VERSION ""

NS_ :

BS_:

BU_: XXX

BO_ 85 CID_FEHZVD: 8 XXX
 SG_ sig_qmhbra : 40|1@1+ (1,0) [0|1] "" XXX
 SG_ sig_kxugde : 56|8@1+ (1,0) [0|255] "" XXX

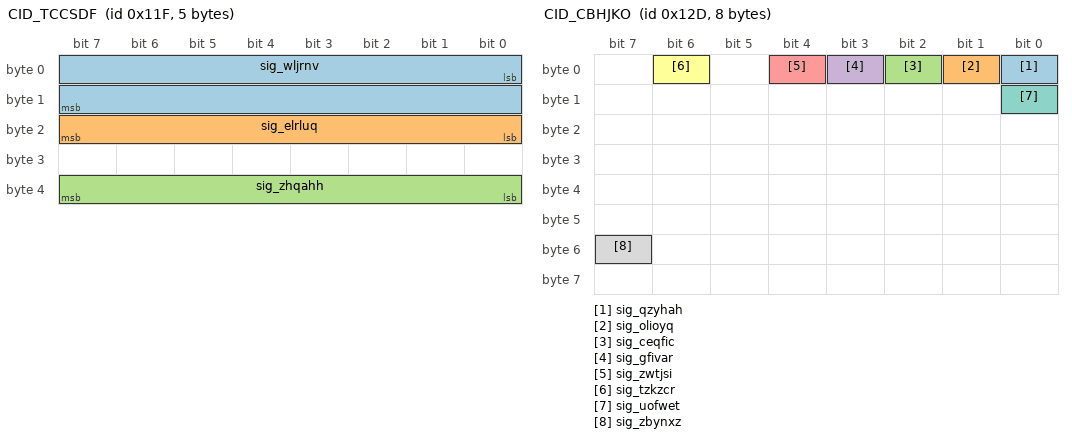
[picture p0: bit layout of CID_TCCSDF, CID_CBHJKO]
BO_ 287 CID_TCCSDF: 5 XXX
 SG_ sig_wljrnv : 0|16@1- (0.1,0) [-450|450] "" XXX
 SG_ sig_elrluq : 16|8@1+ (4,0) [0|1020] "" XXX
 SG_ sig_zhqahh : 32|8@1+ (1,0) [0|255] "" XXX

BO_ 289 CID_QPYSFW: 8 XXX
 SG_ sig_cigpcy : 0|12@1+ (1,0) [0|255] "" XXX

BO_ 301 CID_CBHJKO: 8 XXX
 SG_ sig_qzyhah : 0|1@0+ (1,0) [0|1] "" XXX
 SG_ sig_olioyq : 1|1@0+ (1,0) [0|1] "" XXX
 SG_ sig_ceqfic : 2|1@0+ (1,0) [0|1] "" XXX
 SG_ sig_gfivar : 3|1@0+ (1,0) [0|1] "" XXX
 SG_ sig_zwtjsi : 4|1@0+ (1,0) [0|1] "" XXX
 SG_ sig_tzkzcr : 6|1@0+ (1,0) [0|1] "" XXX
 SG_ sig_uofwet : 8|1@0+ (1,0) [0|1] "" XXX
 SG_ sig_zbynxz : 55|1@0+ (1,0) [0|1] "" XXX

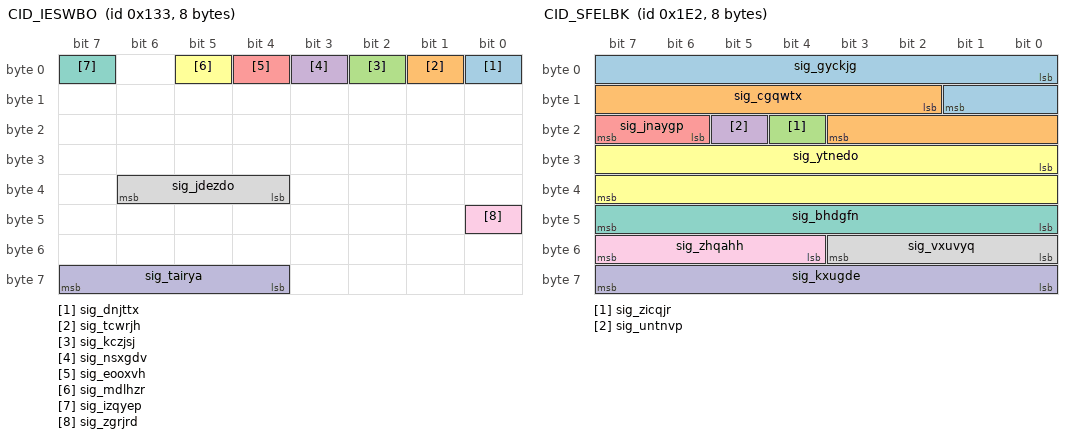
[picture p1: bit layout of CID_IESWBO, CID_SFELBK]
BO_ 307 CID_IESWBO: 8 XXX
 SG_ sig_dnjttx : 0|1@0+ (1,0) [0|1] "" XXX
 SG_ sig_tcwrjh : 1|1@1+ (1,0) [0|1] "" XXX
 SG_ sig_kczjsj : 2|1@1+ (1,0) [0|1] "" XXX
 SG_ sig_nsxgdv : 3|1@1+ (1,0) [0|1] "" XXX
 SG_ sig_eooxvh : 4|1@0+ (1,0) [0|1] "" XXX
 SG_ sig_mdlhzr : 5|1@0+ (1,0) [0|1] "" XXX
 SG_ sig_izqyep : 7|1@0+ (1,0) [0|1] "" XXX
 SG_ sig_jdezdo : 36|3@1+ (1,0) [0|7] "" XXX
 SG_ sig_zgrjrd : 40|1@0+ (1,0) [0|1] "" XXX
 SG_ sig_tairya : 63|4@0+ (1,0) [0|15] "" XXX

BO_ 482 CID_SFELBK: 8 XXX
 SG_ sig_gyckjg : 0|10@1- (0.01,0) [0|5] "" XXX
 SG_ sig_cgqwtx : 10|10@1- (0.01,0) [-5|0] "" XXX
 SG_ sig_zicqjr : 20|1@0+ (1,0) [0|1] "" XXX
 SG_ sig_untnvp : 21|1@0+ (1,0) [0|1] "" XXX
 SG_ sig_jnaygp : 22|2@1+ (1,0) [0|1] "" XXX
 SG_ sig_ytnedo : 24|16@1- (0.1,0) [-780|779.9] "" XXX
 SG_ sig_bhdgfn : 47|8@0+ (1,0) [0|255] "" XXX
 SG_ sig_vxuvyq : 48|4@1+ (1,0) [0|15] "" XXX
 SG_ sig_zhqahh : 52|4@1+ (1,0) [0|15] "" XXX
 SG_ sig_kxugde : 56|8@1+ (1,0) [0|255] "" XXX

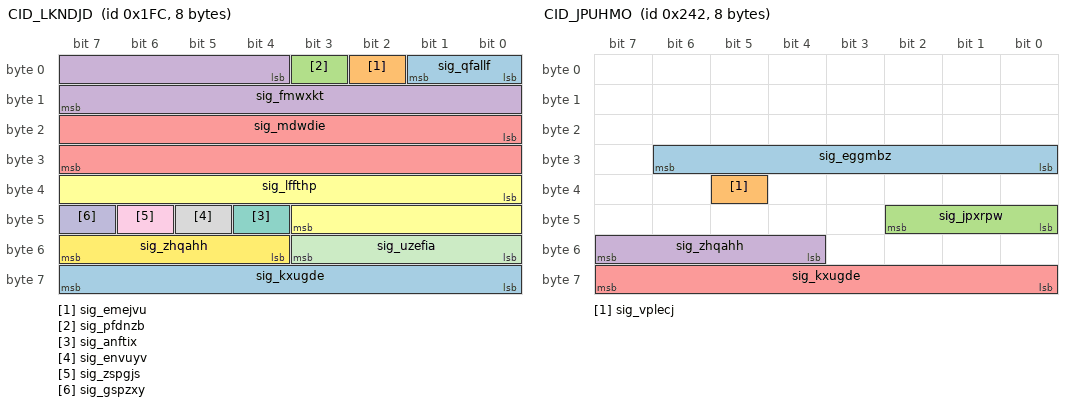
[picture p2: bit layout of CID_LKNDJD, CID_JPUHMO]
BO_ 508 CID_LKNDJD: 8 XXX
 SG_ sig_qfallf : 0|2@1+ (1,0) [0|1] "" XXX
 SG_ sig_emejvu : 2|1@1+ (1,0) [0|1] "" XXX
 SG_ sig_pfdnzb : 3|1@0+ (1,0) [0|1] "" XXX
 SG_ sig_fmwxkt : 4|12@1- (1,0) [-2048|2047] "" XXX
 SG_ sig_mdwdie : 16|16@1- (0.1,0) [-780|779.9] "Deg" XXX
 SG_ sig_lffthp : 32|12@1- (0.01,0) [0|63] "" XXX
 SG_ sig_anftix : 44|1@0+ (1,0) [0|1] "" XXX
 SG_ sig_envuyv : 45|1@1+ (1,0) [0|255] "" XXX
 SG_ sig_zspgjs : 46|1@1+ (1,0) [0|1] "" XXX
 SG_ sig_gspzxy : 47|1@0+ (1,0) [0|3] "" XXX
 SG_ sig_uzefia : 48|4@1+ (1,0) [0|15] "" XXX
 SG_ sig_zhqahh : 52|4@1+ (1,0) [0|15] "" XXX
 SG_ sig_kxugde : 56|8@1+ (1,0) [0|255] "" XXX

BO_ 578 CID_JPUHMO: 8 XXX
 SG_ sig_eggmbz : 30|7@0+ (1,0) [0|127] "" XXX
 SG_ sig_vplecj : 37|1@0+ (1,0) [0|1] "" XXX
 SG_ sig_jpxrpw : 40|3@1+ (1,0) [0|7] "" XXX
 SG_ sig_zhqahh : 55|4@0+ (1,0) [0|15] "" XXX
 SG_ sig_kxugde : 56|8@1+ (1,0) [0|255] "" XXX

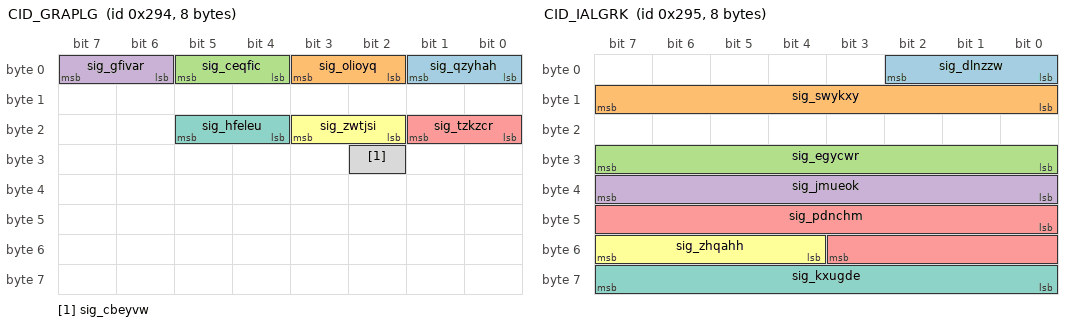
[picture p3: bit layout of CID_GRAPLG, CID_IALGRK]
BO_ 660 CID_GRAPLG: 8 XXX
 SG_ sig_qzyhah : 1|2@0+ (1,0) [0|3] "" XXX
 SG_ sig_olioyq : 3|2@0+ (1,0) [0|3] "" XXX
 SG_ sig_ceqfic : 5|2@0+ (1,0) [0|3] "" XXX
 SG_ sig_gfivar : 7|2@0+ (1,0) [0|3] "" XXX
 SG_ sig_tzkzcr : 17|2@0+ (1,0) [0|3] "" XXX
 SG_ sig_zwtjsi : 19|2@0+ (1,0) [0|3] "" XXX
 SG_ sig_hfeleu : 21|2@0+ (1,0) [0|3] "" XXX
 SG_ sig_cbeyvw : 26|1@0+ (1,0) [0|1] "" XXX

BO_ 661 CID_IALGRK: 8 XXX
 SG_ sig_dlnzzw : 2|3@0+ (1,0) [0|7] "" XXX
 SG_ sig_swykxy : 15|8@0+ (1,0) [0|255] "" XXX
 SG_ sig_egycwr : 31|8@0+ (1,0) [0|255] "" XXX
 SG_ sig_jmueok : 32|8@1+ (1,0) [0|255] "" XXX
 SG_ sig_pdnchm : 40|12@1+ (1,0) [0|255] "" XXX
 SG_ sig_zhqahh : 52|4@1+ (1,0) [0|15] "" XXX
 SG_ sig_kxugde : 63|8@0+ (1,0) [0|255] "" XXX

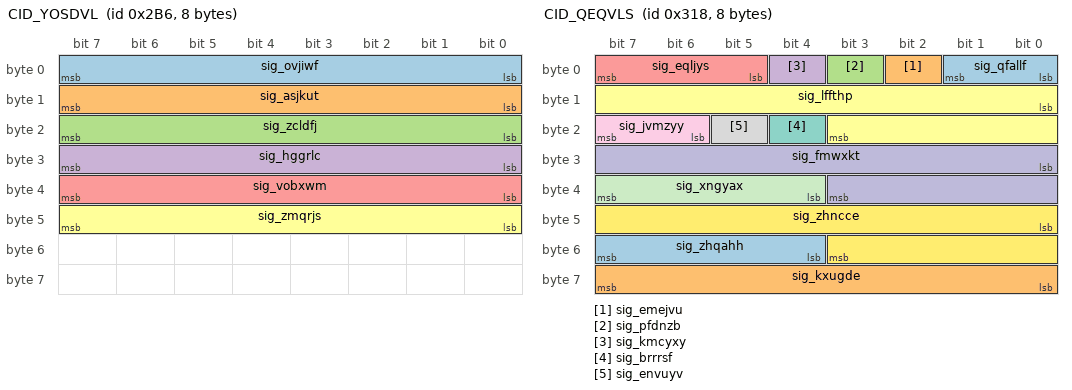
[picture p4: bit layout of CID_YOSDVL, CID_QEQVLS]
BO_ 694 CID_YOSDVL: 8 XXX
 SG_ sig_ovjiwf : 7|8@0+ (1,0) [0|255] "" XXX
 SG_ sig_asjkut : 15|8@0+ (1,0) [0|255] "" XXX
 SG_ sig_zcldfj : 23|8@0+ (1,0) [0|255] "" XXX
 SG_ sig_hggrlc : 31|8@0+ (1,0) [0|255] "" XXX
 SG_ sig_vobxwm : 39|8@0+ (1,0) [0|255] "" XXX
 SG_ sig_zmqrjs : 47|8@0+ (1,0) [0|255] "" XXX

BO_ 790 CID_AJJVXH: 8 XXX
 SG_ sig_zobyvt : 3|4@0+ (1,0) [0|1] "" XXX
 SG_ sig_jdzxlo : 4|2@1+ (1,0) [0|3] "" XXX
 SG_ sig_yfxxrb : 6|2@1+ (1,0) [0|3] "" XXX
 SG_ sig_qwgrkx : 8|2@1+ (1,0) [0|3] "" XXX
 SG_ sig_yecvhz : 10|1@1+ (1,0) [0|1] "" XXX
 SG_ sig_eprusy : 11|4@1+ (1,0) [0|1] "" XXX
 SG_ sig_fukycm : 15|1@0+ (1,0) [0|1] "" XXX
 SG_ sig_ytnedo : 16|11@1- (1,0) [-1024|1023] "" XXX
 SG_ sig_zicqjr : 27|1@1+ (1,0) [0|1] "" XXX
 SG_ sig_untnvp : 28|1@1+ (1,0) [0|3] "" XXX
 SG_ sig_rbdwqk : 29|1@0+ (1,0) [0|1] "" XXX
 SG_ sig_kfhdph : 30|1@0+ (1,0) [0|1] "" XXX
 SG_ sig_cnhsyd : 31|1@0+ (1,0) [0|1] "" XXX
 SG_ sig_dpiwdh : 32|2@1+ (1,0) [0|3] "" XXX
 SG_ sig_bypyaf : 34|2@1+ (1,0) [0|3] "" XXX
 SG_ sig_jbwcur : 36|4@1+ (1,0) [0|3] "" XXX
 SG_ sig_afnoxh : 40|8@1+ (5,-5) [-5|1270] "" XXX
 SG_ sig_ldiurk : 49|2@0+ (1,0) [0|3] "" XXX
 SG_ sig_oraarg : 51|2@0+ (1,0) [0|3] "" XXX
 SG_ sig_zhqahh : 52|4@1+ (1,0) [0|15] "" XXX
 SG_ sig_kxugde : 56|8@1+ (1,0) [0|15] "" XXX

BO_ 792 CID_QEQVLS: 8 XXX
 SG_ sig_qfallf : 0|2@1+ (1,0) [0|1] "" XXX
 SG_ sig_emejvu : 2|1@1+ (1,0) [0|1] "" XXX
 SG_ sig_pfdnzb : 3|1@1+ (1,0) [0|1] "" XXX
 SG_ sig_kmcyxy : 4|1@1+ (1,0) [0|1] "" XXX
 SG_ sig_eqljys : 5|3@1+ (1,0) [0|1] "" XXX
 SG_ sig_lffthp : 8|12@1- (1,0) [-2048|2047] "" XXX
 SG_ sig_brrrsf : 20|1@1+ (1,0) [0|1] "" XXX
 SG_ sig_envuyv : 21|1@1+ (1,0) [0|1] "" XXX
 SG_ sig_jvmzyy : 22|2@1+ (1,0) [0|15] "" XXX
 SG_ sig_fmwxkt : 24|12@1- (1,0) [-2048|2047] "" XXX
 SG_ sig_xngyax : 36|4@1+ (1,0) [0|15] "" XXX
 SG_ sig_zhncce : 40|12@1+ (1,0) [0|4095] "" XXX
 SG_ sig_zhqahh : 52|4@1+ (1,0) [0|15] "" XXX
 SG_ sig_kxugde : 56|8@1+ (1,0) [0|255] "" XXX

BO_ 813 CID_VZRXUR: 8 XXX
 SG_ sig_nuzjrv : 0|9@1+ (0.5,0) [0|255.5] "" XXX
 SG_ sig_pdpbla : 9|1@1+ (1,0) [0|1] "" XXX
 SG_ sig_qodzcs : 10|3@1+ (1,0) [0|7] "" XXX
 SG_ sig_lpfock : 13|3@1+ (1,0) [0|7] "" XXX
 SG_ sig_yarggu : 16|1@1+ (1,0) [0|1] "" XXX
 SG_ sig_ebcyai : 17|1@1+ (1,0) [0|1] "" XXX
 SG_ sig_pfdnzb : 18|1@1+ (1,0) [0|1] "" XXX
 SG_ sig_widamr : 19|3@1+ (1,0) [0|1] "" XXX
 SG_ sig_vgwcfa : 22|1@0+ (1,0) [0|1] "" XXX
 SG_ sig_ndntoh : 23|1@0+ (1,0) [0|1] "" XXX
 SG_ sig_qwgrkx : 24|1@1+ (1,0) [0|1] "" XXX
 SG_ sig_omlxtv : 25|7@1+ (1,0) [0|127] "" XXX
 SG_ sig_ugdwaw : 32|4@1+ (1,0) [0|15] "" XXX
 SG_ sig_gipksh : 36|12@1+ (1,0) [0|4095] "" XXX
 SG_ sig_zhqahh : 48|4@1+ (1,0) [0|15] "" XXX
 SG_ sig_mjmmij : 55|4@0+ (1,0) [0|15] "" XXX
 SG_ sig_kxugde : 56|8@1+ (1,0) [0|255] "" XXX

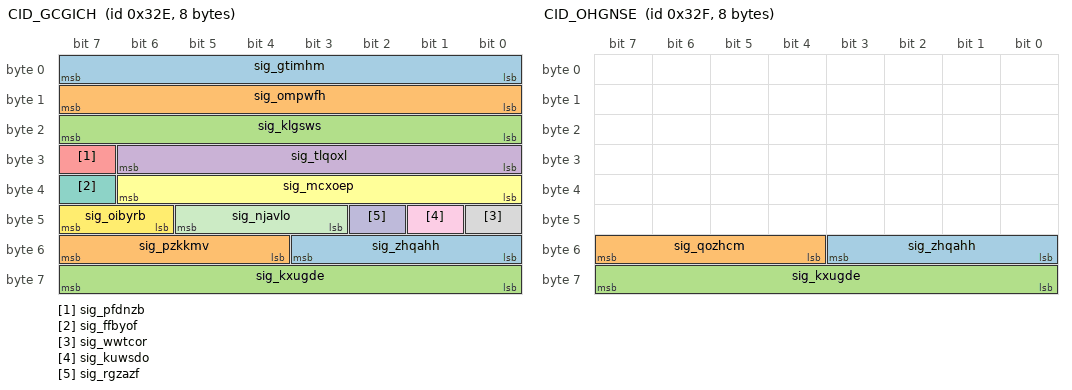
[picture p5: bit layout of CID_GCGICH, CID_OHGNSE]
BO_ 814 CID_GCGICH: 8 XXX
 SG_ sig_gtimhm : 0|8@1+ (0.05,-5) [-100|155] "" XXX
 SG_ sig_ompwfh : 8|8@1+ (0.05,-5) [0|1.26] "" XXX
 SG_ sig_klgsws : 16|8@1+ (0.05,-5) [0|1.26] "" XXX
 SG_ sig_tlqoxl : 24|7@1+ (0.2,0) [0|12.7] "" XXX
 SG_ sig_pfdnzb : 31|1@0+ (1,0) [0|1] "" XXX
 SG_ sig_mcxoep : 32|7@1+ (0.2,-16) [0|12.7] "" XXX
 SG_ sig_ffbyof : 39|1@0+ (1,0) [0|1] "" XXX
 SG_ sig_wwtcor : 40|1@0+ (1,0) [0|1] "" XXX
 SG_ sig_kuwsdo : 41|1@0+ (1,0) [0|1] "" XXX
 SG_ sig_rgzazf : 42|1@1+ (1,0) [0|3] "" XXX
 SG_ sig_njavlo : 45|3@0+ (1,0) [0|1] "" XXX
 SG_ sig_oibyrb : 46|2@1+ (1,0) [0|3] "" XXX
 SG_ sig_zhqahh : 48|4@1+ (1,0) [0|15] "" XXX
 SG_ sig_pzkkmv : 55|4@0+ (1,0) [0|15] "" XXX
 SG_ sig_kxugde : 56|8@1+ (1,0) [0|255] "" XXX

BO_ 815 CID_OHGNSE: 8 XXX
 SG_ sig_zhqahh : 48|4@1+ (1,0) [0|15] "" XXX
 SG_ sig_qozhcm : 55|4@0+ (1,0) [0|15] "" XXX
 SG_ sig_kxugde : 56|8@1+ (1,0) [0|255] "" XXX

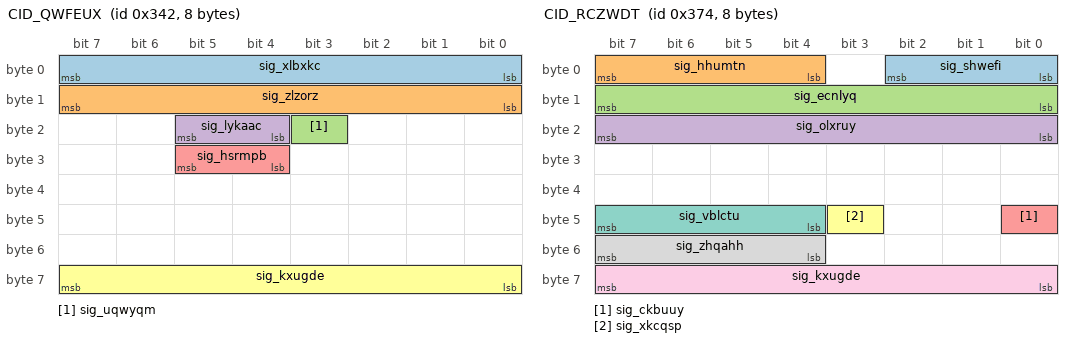
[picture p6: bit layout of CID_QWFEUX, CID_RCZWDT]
BO_ 834 CID_QWFEUX: 8 XXX
 SG_ sig_xlbxkc : 0|8@1+ (0.01,0) [0|2.55] "" XXX
 SG_ sig_zlzorz : 8|8@1+ (0.01,0) [0|2.55] "" XXX
 SG_ sig_uqwyqm : 19|1@1+ (1,0) [0|1] "" XXX
 SG_ sig_lykaac : 20|2@1+ (1,0) [0|255] "" XXX
 SG_ sig_hsrmpb : 28|2@1+ (1,0) [0|1] "" XXX
 SG_ sig_kxugde : 56|8@1+ (1,0) [0|255] "" XXX

 BO_ 884 CID_RCZWDT: 8 MRR
 SG_ sig_shwefi : 2|3@0+ (1,0) [0|3] "" MRR
 SG_ sig_hhumtn : 7|4@0+ (1,0) [0|15] "" MRR
 SG_ sig_ecnlyq : 15|8@0+ (0.1,-12) [0|255] "" MRR
 SG_ sig_olxruy : 23|8@0+ (1,-100) [0|255] "" MRR
 SG_ sig_ckbuuy : 40|1@0+ (1,0) [0|3] "" MRR
 SG_ sig_xkcqsp : 43|1@0+ (1,0) [0|1] "" XXX
 SG_ sig_vblctu : 44|4@1+ (1,0) [0|15] "" XXX
 SG_ sig_zhqahh : 52|4@1+ (1,0) [0|15] "" MRR
 SG_ sig_kxugde : 56|8@1+ (1,0) [0|255] "" MRR

BO_ 944 CID_PBRDYR: 8 XXX
 SG_ sig_cgiicb : 1|2@0+ (1,0) [0|3] "" XXX
 SG_ sig_aehlgk : 2|1@0+ (1,0) [0|1] "" XXX
 SG_ sig_raioaw : 4|2@0+ (1,0) [0|3] "" XXX
 SG_ sig_imcpgd : 5|1@0+ (1,0) [0|1] "" XXX
 SG_ sig_nlfbhz : 6|1@0+ (1,0) [0|1] "" XXX
 SG_ sig_tyapnt : 7|1@0+ (1,0) [0|1] "" XXX
 SG_ sig_slcfmw : 8|1@0+ (1,0) [0|1] "" XXX
 SG_ sig_uplmfi : 11|3@0+ (1,0) [0|7] "" XXX
 SG_ sig_blzoka : 12|1@0+ (1,0) [0|1] "" XXX
 SG_ sig_gkzrtm : 14|2@0+ (1,0) [0|3] "" XXX
 SG_ sig_trtvyj : 15|1@0+ (1,0) [0|1] "" XXX
 SG_ sig_mdyzqa : 16|1@0+ (1,0) [0|1] "" XXX
 SG_ sig_tfmfrk : 18|2@0+ (1,0) [0|3] "" XXX
 SG_ sig_jyafte : 19|1@0+ (1,0) [0|1] "" XXX
 SG_ sig_vgmdtp : 23|4@0+ (1,0) [0|15] "" XXX
 SG_ sig_qbowdu : 24|28@1+ (1,0) [0|268435455] "" XXX
 SG_ sig_zhqahh : 52|4@1+ (1,0) [0|15] "" XXX
 SG_ sig_kxugde : 56|8@1+ (1,0) [0|255] "" XXX

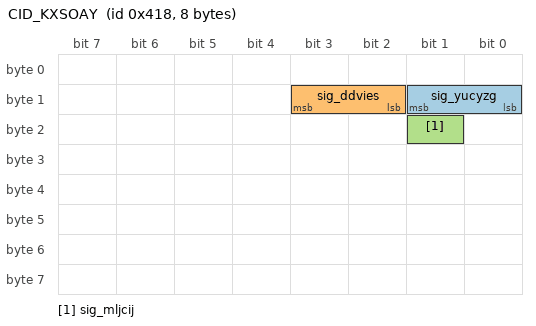
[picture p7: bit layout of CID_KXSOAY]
BO_ 1048 CID_KXSOAY: 8 XXX
 SG_ sig_yucyzg : 9|2@0+ (1,0) [0|1] "" XXX
 SG_ sig_ddvies : 11|2@0+ (1,0) [0|1] "" XXX
 SG_ sig_mljcij : 17|1@0+ (1,0) [0|1] "" XXX

VAL_ 578 sig_jpxrpw 4 "D" 2 "R" 3 "N" 1 "P";
VAL_ 790 sig_zobyvt 11 "AutoFullBeamActive" 2 "AutoFullBeamInactive";
VAL_ 790 sig_jdzxlo 0 "GRAY" 1 "GREEN" 2 "YELLOW" 3 "RED";
VAL_ 790 sig_yfxxrb 3 "ALARM_AND_LKA" 2 "LKA" 1 "ALARM" 0 "DISABLE";
VAL_ 790 sig_bypyaf 0 "GRAY" 1 "GREEN" 2 "YELLOW" 3 "RED";
VAL_ 790 sig_ldiurk 0 "VIBRATION" 1 "AUDIO" 2 "AUDIO_AND_VIBRATION";
VAL_ 792 sig_qfallf 0 "NotReady" 1 "Ready" 2 "Active" 3 "TemporaryFail";
VAL_ 813 sig_qodzcs 4 "4BAR" 3 "3BAR" 2 "2BAR" 1 "1BAR";
VAL_ 813 sig_widamr 0 "OFF" 2 "ACC_ON" 3 "ACC_ACTIVE" 5 "FORCE_ACCEL" 7 "ERROR";
VAL_ 813 sig_omlxtv 36 "ACC_ERROR" 22 "OVERRIDE" 12 "ENGAGE" 8 "DISENGAGE" 20 "ACC_ON" 32 "ACC_OFF" 48 "CHECK_GEAR_D" 16 "FORCE_ACCEL" 0 "NONE";
VAL_ 814 sig_njavlo 0 "Off" 1 "Passive" 2 "StandBy" 3 "ActiveControl" 4 "BrakeOnly" 5 "Override" 6 "Standstill" 7 "Failure";
VAL_ 814 sig_oibyrb 0 "Softoff" 1 "Fastoff" 2 "Immediateoff" 3 "Initial";
VAL_ 834 sig_lykaac 2 "SPORT" 1 "ECO" 0 "SNOW";
VAL_ 834 sig_hsrmpb 3 "HEV" 2 "FORCE_EV" 1 "EV";
VAL_ 944 sig_raioaw 0 "NOTPRESSED" 1 "DOWN_SETSPEED" 3 "UP_RESETSPEED";
